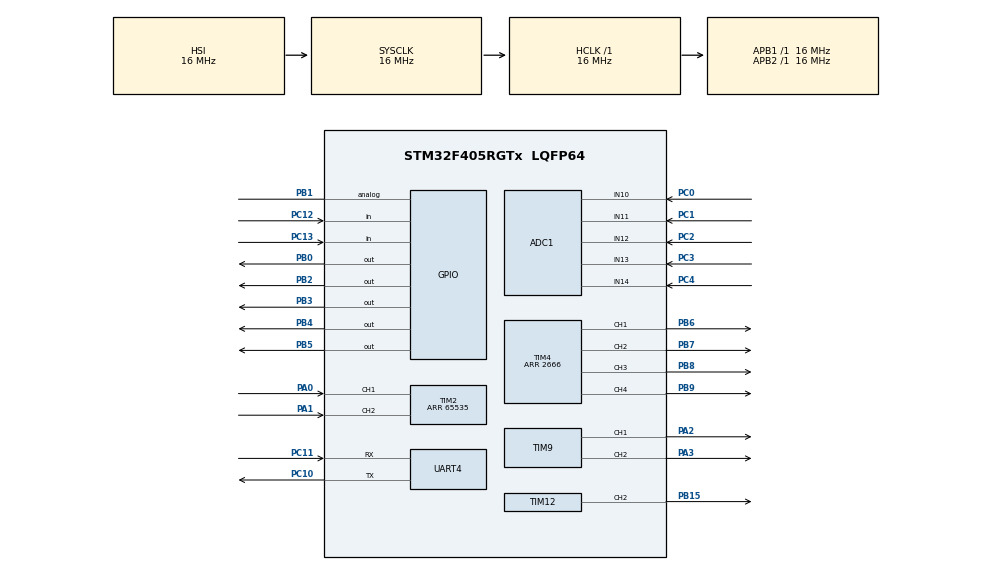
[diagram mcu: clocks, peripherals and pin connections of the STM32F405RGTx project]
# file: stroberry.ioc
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ADC1.Channel-0\#ChannelRegularConversion=ADC_CHANNEL_10
ADC1.NbrOfConversionFlag=1
ADC1.Rank-0\#ChannelRegularConversion=1
ADC1.SamplingTime-0\#ChannelRegularConversion=ADC_SAMPLETIME_3CYCLES
ADC1.master=1
Mcu.Family=STM32F4
Mcu.Name=STM32F405RGTx
Mcu.Package=LQFP64
NVIC.PriorityGroup=NVIC_PRIORITYGROUP_4
PA0-WKUP.Signal=S_TIM2_CH1_ETR
PA1.Signal=S_TIM2_CH2
PA13.Signal=SYS_JTMS-SWDIO
PA14.Signal=SYS_JTCK-SWCLK
PA2.Signal=S_TIM9_CH1
PA3.Signal=S_TIM9_CH2
PA4.Signal=SPI1_NSS
PA5.Signal=SPI1_SCK
PA6.Signal=SPI1_MISO
PA7.Signal=SPI1_MOSI
PB0.Signal=GPIO_Output
PB1.Signal=GPIO_Analog
PB15.Signal=S_TIM12_CH2
PB2.Signal=GPIO_Output
PB3.Signal=GPIO_Output
PB4.Signal=GPIO_Output
PB5.Signal=GPIO_Output
PB6.Signal=S_TIM4_CH1
PB7.Signal=S_TIM4_CH2
PB8.Signal=S_TIM4_CH3
PB9.Signal=S_TIM4_CH4
PC0.Signal=ADCx_IN10
PC1.Signal=ADCx_IN11
PC10.Mode=Asynchronous
PC10.Signal=UART4_TX
PC11.Mode=Asynchronous
PC11.Signal=UART4_RX
PC12.Signal=GPIO_Input
PC13-ANTI_TAMP.Signal=GPIO_Input
PC2.Signal=ADCx_IN12
PC3.Signal=ADCx_IN13
PC4.Signal=ADCx_IN14
PC6.Signal=S_TIM8_CH1
ProjectManager.HeapSize=0x200
ProjectManager.StackSize=0x400
ProjectManager.TargetToolchain=Makefile
RCC.AHBFreq_Value=16000000
RCC.APB1Freq_Value=16000000
RCC.APB2Freq_Value=16000000
RCC.CortexFreq_Value=16000000
RCC.HSE_VALUE=25000000
RCC.HSI_VALUE=16000000
RCC.LSE_VALUE=32768
RCC.SYSCLKFreq_VALUE=16000000
RCC.VCOOutputFreq_Value=192000000
SH.ADCx_IN10.0=ADC1_IN10,IN10
SH.ADCx_IN11.0=ADC1_IN11,IN11
SH.ADCx_IN12.0=ADC1_IN12,IN12
SH.ADCx_IN13.0=ADC1_IN13,IN13
SH.ADCx_IN14.0=ADC1_IN14,IN14
SH.S_TIM12_CH2.0=TIM12_CH2,PWM Generation2 CH2
SH.S_TIM2_CH1_ETR.0=TIM2_CH1,Encoder_Interface
SH.S_TIM2_CH2.0=TIM2_CH2,Encoder_Interface
SH.S_TIM4_CH1.0=TIM4_CH1,PWM Generation1 CH1
SH.S_TIM4_CH2.0=TIM4_CH2,PWM Generation2 CH2
SH.S_TIM4_CH3.0=TIM4_CH3,PWM Generation3 CH3
SH.S_TIM4_CH4.0=TIM4_CH4,PWM Generation4 CH4
SH.S_TIM8_CH1.0=TIM8_CH1
SH.S_TIM9_CH1.0=TIM9_CH1,PWM Generation1 CH1
SH.S_TIM9_CH2.0=TIM9_CH2,PWM Generation2 CH2
TIM12.Channel-PWM\ Generation2\ CH2=TIM_CHANNEL_2
TIM2.Period=65535
TIM4.Channel-PWM\ Generation1\ CH1=TIM_CHANNEL_1
TIM4.Channel-PWM\ Generation2\ CH2=TIM_CHANNEL_2
TIM4.Channel-PWM\ Generation3\ CH3=TIM_CHANNEL_3
TIM4.Channel-PWM\ Generation4\ CH4=TIM_CHANNEL_4
TIM4.Period=2666
TIM9.Channel-PWM\ Generation1\ CH1=TIM_CHANNEL_1
TIM9.Channel-PWM\ Generation2\ CH2=TIM_CHANNEL_2
UART4.VirtualMode=Asynchronous
VP_TIM4_VS_ClockSourceINT.Mode=Internal
board=custom

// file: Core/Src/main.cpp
/* USER CODE BEGIN Header */
/**
  ******************************************************************************
  * @file           : main.c
  * @brief          : Main program body
  ******************************************************************************
  * @attention
  *
  * <h2><center>&copy; Copyright (c) 2022 STMicroelectronics.
  * All rights reserved.</center></h2>
  *
  * This software component is licensed by ST under BSD 3-Clause license,
  * the "License"; You may not use this file except in compliance with the
  * License. You may obtain a copy of the License at:
  *                        opensource.org/licenses/BSD-3-Clause
  *
  ******************************************************************************
  */
/* USER CODE END Header */
#include "main.h"
#include "adc.h"
#include "tim.h"
#include "usart.h"
#include "gpio.h"

/* USER CODE BEGIN Includes */
#include "mine.h"
/* USER CODE END Includes */

void SystemClock_Config(void);

int main(void)
{
  /* USER CODE BEGIN 1 */
  std::vector<int>v(0);
  /* USER CODE END 1 */

  /* MCU Configuration--------------------------------------------------------*/

  /* Reset of all peripherals, Initializes the Flash interface and the Systick. */
  HAL_Init();

  /* Configure the system clock */
  SystemClock_Config();

  /* Initialize all configured peripherals */
  MX_GPIO_Init();
  MX_ADC1_Init();
  MX_TIM2_Init();
  MX_TIM4_Init();
  MX_TIM9_Init();
  MX_TIM12_Init();
  MX_UART4_Init();
  /* USER CODE BEGIN 2 */
  v.push_back(1);
  /* USER CODE END 2 */

  /* Infinite loop */
  while (1)
  {

  }
}

void SystemClock_Config(void)
{
  RCC_OscInitTypeDef RCC_OscInitStruct = {0};
  RCC_ClkInitTypeDef RCC_ClkInitStruct = {0};

  /** Configure the main internal regulator output voltage
  */
  __HAL_RCC_PWR_CLK_ENABLE();
  __HAL_PWR_VOLTAGESCALING_CONFIG(PWR_REGULATOR_VOLTAGE_SCALE1);
  /** Initializes the RCC Oscillators according to the specified parameters
  * in the RCC_OscInitTypeDef structure.
  */
  RCC_OscInitStruct.OscillatorType = RCC_OSCILLATORTYPE_HSI;
  RCC_OscInitStruct.HSIState = RCC_HSI_ON;
  RCC_OscInitStruct.HSICalibrationValue = RCC_HSICALIBRATION_DEFAULT;
  RCC_OscInitStruct.PLL.PLLState = RCC_PLL_NONE;
  if (HAL_RCC_OscConfig(&RCC_OscInitStruct) != HAL_OK)
  {
    Error_Handler();
  }
  /** Initializes the CPU, AHB and APB buses clocks
  */
  RCC_ClkInitStruct.ClockType = RCC_CLOCKTYPE_HCLK|RCC_CLOCKTYPE_SYSCLK
                              |RCC_CLOCKTYPE_PCLK1|RCC_CLOCKTYPE_PCLK2;
  RCC_ClkInitStruct.SYSCLKSource = RCC_SYSCLKSOURCE_HSI;
  RCC_ClkInitStruct.AHBCLKDivider = RCC_SYSCLK_DIV1;
  RCC_ClkInitStruct.APB1CLKDivider = RCC_HCLK_DIV1;
  RCC_ClkInitStruct.APB2CLKDivider = RCC_HCLK_DIV1;

  if (HAL_RCC_ClockConfig(&RCC_ClkInitStruct, FLASH_LATENCY_0) != HAL_OK)
  {
    Error_Handler();
  }
}

/* USER CODE BEGIN 4 */
int _write(int file, char *ptr, int len)
{
  HAL_UART_Transmit(&huart4, (uint8_t *)ptr, len, 10);
  return len;
}
/* USER CODE END 4 */

void Error_Handler(void)
{
  __disable_irq();
  while (1)
  {
  }
}

/************************ (C) COPYRIGHT STMicroelectronics *****END OF FILE****/
